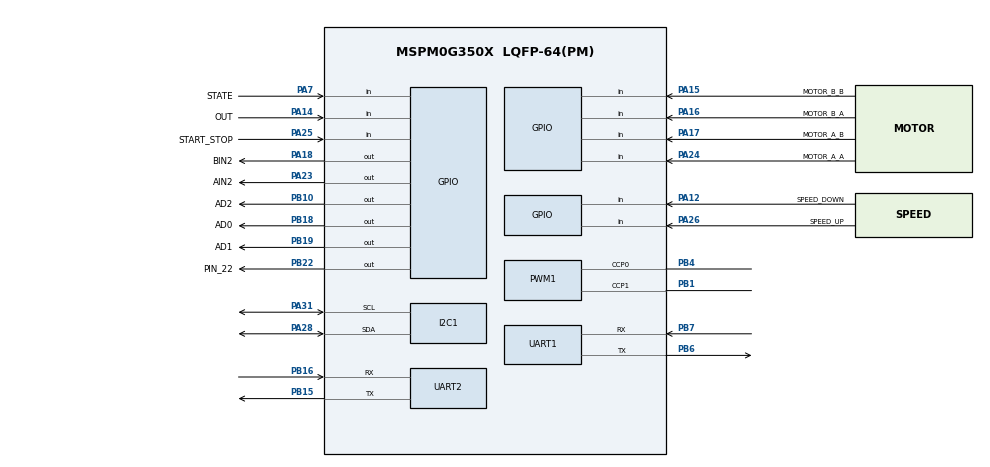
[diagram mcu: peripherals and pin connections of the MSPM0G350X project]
/**
 * Tianmengxing MSPM0G3507 competition expansion board (2026-07-24).
 *
 * Pin map:
 *   8-way grayscale: digital OUT PA14, AD0 PB18, AD1 PB19, AD2 PB10
 *   AT8236 motor A:  AIN1 PB4/TIMA1.CCP0, AIN2 PA23
 *   AT8236 motor B:  BIN1 PB1/TIMA1.CCP1, BIN2 PA18
 *   encoder A:       B PA17, A PA24
 *   encoder B:       B PA15, A PA16
 *   OLED:            I2C0 SDA PA28, SCL PA31
 *   keys:            PA25 start/stop, PA26 speed+, PA12 speed- (active low)
 *   debug UART:      UART1 TX PB6, RX PB7
 *   HC-05:           UART2 TX PB15, RX PB16, STATE PA7
 *
 * @cliArgs --device "MSPM0G350X" --part "Default" --package "LQFP-64(PM)" --product "mspm0_sdk@2.11.00.07"
 * @versions {"tool":"1.28.0"}
 */

const GPIO    = scripting.addModule("/ti/driverlib/GPIO", {}, false);
const GPIO1   = GPIO.addInstance();
const GPIO2   = GPIO.addInstance();
const GPIO3   = GPIO.addInstance();
const GPIO4   = GPIO.addInstance();
const GPIO5   = GPIO.addInstance();
const GPIO6   = GPIO.addInstance();
const GPIO7   = GPIO.addInstance();
const I2C     = scripting.addModule("/ti/driverlib/I2C", {}, false);
const I2C1    = I2C.addInstance();
const PWM     = scripting.addModule("/ti/driverlib/PWM", {}, false);
const PWM1    = PWM.addInstance();
const SYSCTL  = scripting.addModule("/ti/driverlib/SYSCTL");
const UART    = scripting.addModule("/ti/driverlib/UART", {}, false);
const UART1   = UART.addInstance();
const UART2   = UART.addInstance();

const divider9 = system.clockTree["UDIV"];
divider9.divideValue = 2;

const mux4 = system.clockTree["EXHFMUX"];
mux4.inputSelect = "EXHFMUX_XTAL";

const mux8 = system.clockTree["HSCLKMUX"];
mux8.inputSelect = "HSCLKMUX_SYSPLL2X";

const mux12 = system.clockTree["SYSPLLMUX"];
mux12.inputSelect = "zSYSPLLMUX_HFCLK";

const pinFunction4 = system.clockTree["HFXT"];
pinFunction4.inputFreq = 40;
pinFunction4.enable = true;
pinFunction4.HFCLKMonitor = true;
pinFunction4.HFXTStartup = 20;

/* On-board status LED. */
GPIO1.$name = "LED";
GPIO1.associatedPins[0].$name = "PIN_22";
GPIO1.associatedPins[0].ioStructure = "SD";
GPIO1.associatedPins[0].assignedPort = "PORTB";
GPIO1.associatedPins[0].assignedPin = "22";
GPIO1.associatedPins[0].pin.$assign = "PB22";

/* Three address inputs on the 8-way grayscale sensor. */
GPIO2.$name = "GRAY_SELECT";
GPIO2.port = "PORTB";
GPIO2.associatedPins.create(3);
GPIO2.associatedPins[0].$name = "AD0";
GPIO2.associatedPins[0].assignedPin = "18";
GPIO2.associatedPins[0].pin.$assign = "PB18";
GPIO2.associatedPins[1].$name = "AD1";
GPIO2.associatedPins[1].assignedPin = "19";
GPIO2.associatedPins[1].pin.$assign = "PB19";
GPIO2.associatedPins[2].$name = "AD2";
GPIO2.associatedPins[2].assignedPin = "10";
GPIO2.associatedPins[2].pin.$assign = "PB10";

/* The sensor's multiplexed OUT signal is a digital, active-high input. */
GPIO7.$name = "GRAY_OUT";
GPIO7.port = "PORTA";
GPIO7.associatedPins[0].$name = "OUT";
GPIO7.associatedPins[0].direction = "INPUT";
GPIO7.associatedPins[0].internalResistor = "PULL_DOWN";
GPIO7.associatedPins[0].assignedPin = "14";
GPIO7.associatedPins[0].pin.$assign = "PA14";

/* The second input of each AT8236 half bridge selects direction. */
GPIO3.$name = "MOTOR_DIR";
GPIO3.port = "PORTA";
GPIO3.associatedPins.create(2);
GPIO3.associatedPins[0].$name = "AIN2";
GPIO3.associatedPins[0].assignedPin = "23";
GPIO3.associatedPins[0].pin.$assign = "PA23";
GPIO3.associatedPins[1].$name = "BIN2";
GPIO3.associatedPins[1].assignedPin = "18";
GPIO3.associatedPins[1].pin.$assign = "PA18";

/* Both edges of both quadrature signals are counted in one GPIO IRQ. */
GPIO4.$name = "ENCODER";
GPIO4.port = "PORTA";
GPIO4.associatedPins.create(4);
GPIO4.associatedPins[0].$name = "MOTOR_A_B";
GPIO4.associatedPins[0].direction = "INPUT";
GPIO4.associatedPins[0].interruptEn = true;
GPIO4.associatedPins[0].polarity = "RISE_FALL";
GPIO4.associatedPins[0].assignedPin = "17";
GPIO4.associatedPins[0].pin.$assign = "PA17";
GPIO4.associatedPins[1].$name = "MOTOR_A_A";
GPIO4.associatedPins[1].direction = "INPUT";
GPIO4.associatedPins[1].interruptEn = true;
GPIO4.associatedPins[1].polarity = "RISE_FALL";
GPIO4.associatedPins[1].assignedPin = "24";
GPIO4.associatedPins[1].pin.$assign = "PA24";
GPIO4.associatedPins[2].$name = "MOTOR_B_B";
GPIO4.associatedPins[2].direction = "INPUT";
GPIO4.associatedPins[2].interruptEn = true;
GPIO4.associatedPins[2].polarity = "RISE_FALL";
GPIO4.associatedPins[2].assignedPin = "15";
GPIO4.associatedPins[2].pin.$assign = "PA15";
GPIO4.associatedPins[3].$name = "MOTOR_B_A";
GPIO4.associatedPins[3].direction = "INPUT";
GPIO4.associatedPins[3].interruptEn = true;
GPIO4.associatedPins[3].polarity = "RISE_FALL";
GPIO4.associatedPins[3].assignedPin = "16";
GPIO4.associatedPins[3].pin.$assign = "PA16";

/* Optional HC-05 STATE wire. */
GPIO5.$name = "HC05";
GPIO5.port = "PORTA";
GPIO5.associatedPins[0].$name = "STATE";
GPIO5.associatedPins[0].direction = "INPUT";
GPIO5.associatedPins[0].assignedPin = "7";
GPIO5.associatedPins[0].pin.$assign = "PA7";

/* Three expansion-board keys, active low. */
GPIO6.$name = "BUTTONS";
GPIO6.port = "PORTA";
GPIO6.associatedPins.create(3);
GPIO6.associatedPins[0].$name = "START_STOP";
GPIO6.associatedPins[0].direction = "INPUT";
GPIO6.associatedPins[0].internalResistor = "PULL_UP";
GPIO6.associatedPins[0].assignedPin = "25";
GPIO6.associatedPins[0].pin.$assign = "PA25";
GPIO6.associatedPins[1].$name = "SPEED_UP";
GPIO6.associatedPins[1].direction = "INPUT";
GPIO6.associatedPins[1].internalResistor = "PULL_UP";
GPIO6.associatedPins[1].assignedPin = "26";
GPIO6.associatedPins[1].pin.$assign = "PA26";
GPIO6.associatedPins[2].$name = "SPEED_DOWN";
GPIO6.associatedPins[2].direction = "INPUT";
GPIO6.associatedPins[2].internalResistor = "PULL_UP";
GPIO6.associatedPins[2].assignedPin = "12";
GPIO6.associatedPins[2].pin.$assign = "PA12";

/* AT8236 PWM inputs, 10 kHz at the configured 80 MHz CPU clock. */
PWM1.$name = "MOTOR_PWM";
PWM1.timerStartTimer = true;
PWM1.clockDivider = 8;
PWM1.peripheral.$assign = "TIMA1";
PWM1.peripheral.ccp0Pin.$assign = "PB4";
PWM1.peripheral.ccp1Pin.$assign = "PB1";
PWM1.PWM_CHANNEL_0.$name = "AIN1_PWM";
PWM1.PWM_CHANNEL_0.ccValue = 1000;
PWM1.PWM_CHANNEL_0.invert = true;
PWM1.PWM_CHANNEL_1.$name = "BIN1_PWM";
PWM1.PWM_CHANNEL_1.ccValue = 1000;
PWM1.PWM_CHANNEL_1.invert = true;

/* Four-pin SSD1306 OLED connector. */
I2C1.$name = "OLED_I2C";
I2C1.basicEnableController = true;
I2C1.basicControllerBusSpeed = 400000;
I2C1.peripheral.$assign = "I2C0";
I2C1.peripheral.sdaPin.$assign = "PA28";
I2C1.peripheral.sclPin.$assign = "PA31";

/* Expansion-board debug header H1. */
UART1.$name = "UART_0";
UART1.targetBaudRate = 115200;
UART1.peripheral.$assign = "UART1";
UART1.peripheral.rxPin.$assign = "PB7";
UART1.peripheral.txPin.$assign = "PB6";
UART1.txPinConfig.enableConfig = true;
UART1.txPinConfig.internalResistor = "PULL_UP";
UART1.rxPinConfig.enableConfig = true;
UART1.rxPinConfig.internalResistor = "PULL_UP";

/* Preserve the original external HC-05 connection. */
UART2.uartClkDiv = "4";
UART2.targetBaudRate = 9600;
UART2.enabledInterrupts = ["RX"];
UART2.$name = "UART_2";
UART2.peripheral.$assign = "UART2";
UART2.peripheral.rxPin.$assign = "PB16";
UART2.peripheral.txPin.$assign = "PB15";

SYSCTL.forceDefaultClkConfig = true;
SYSCTL.clockTreeEn = true;
SYSCTL.validateClkStatus = true;

const Board = scripting.addModule("/ti/driverlib/Board", {}, false);

pinFunction4.peripheral.$suggestSolution = "SYSCTL";
pinFunction4.peripheral.hfxInPin.$suggestSolution = "PA5";
pinFunction4.peripheral.hfxOutPin.$suggestSolution = "PA6";
Board.peripheral.$suggestSolution = "DEBUGSS";
Board.peripheral.swclkPin.$suggestSolution = "PA20";
Board.peripheral.swdioPin.$suggestSolution = "PA19";
